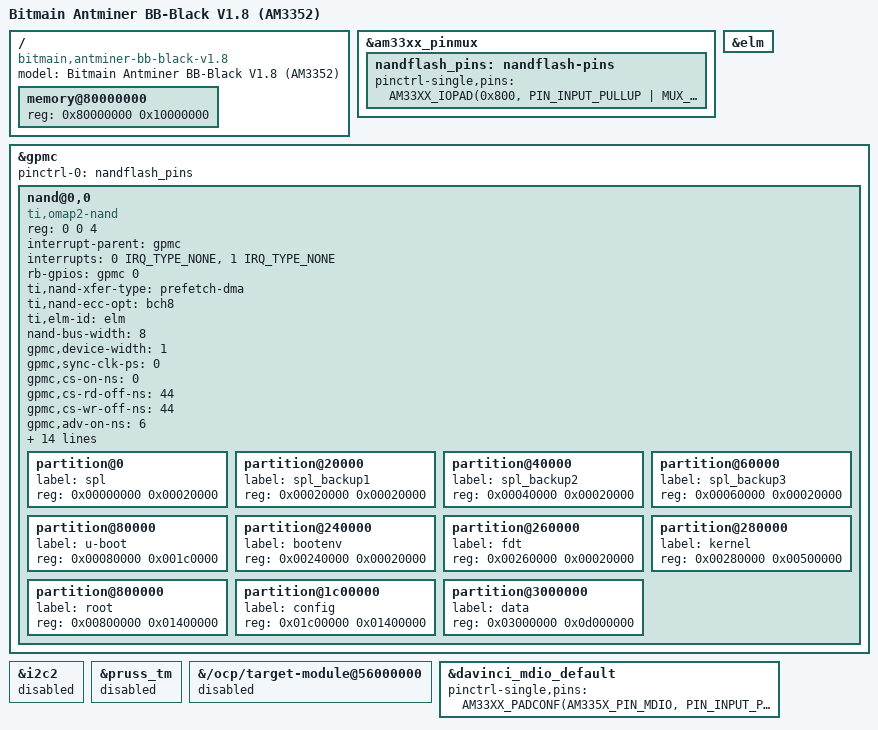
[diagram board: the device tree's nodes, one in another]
// SPDX-License-Identifier: GPL-2.0-only
/*
 * Bitmain Antminer BB-Black V1.8 controller board (AM3352) - fixed part.
 *
 * Everything that is the same on every board: SoC, 256 MiB DDR3, NAND (BCH8+ELM, Bitmain
 * partition layout + 208 MiB "data"), Ethernet (SMSC LAN8710, MII), TPS65217 on I2C0,
 * console UART0, the four BeagleBone user LEDs, microSD slot.
 *
 * Everything per board (pinmux of the free pads, UART1/2/4/5, I2C2, SPI, PWM, CAN, ADC
 * channels, GPIO names/levels) is generated by pinmux/gen-dts.py from a YAML profile into
 * the board .dts that includes this file. Do not add pinmux here.
 *
 * Linux-3.8 label -> mainline label for the UARTs on this SoC:
 *   serial@44e09000 hwmod uart1 -> &uart0 (console, ttyS0)
 *   serial@48022000 hwmod uart2 -> &uart1 ... serial@481aa000 hwmod uart6 -> &uart5
 * GPIO banks: 3.8 "gpio1".."gpio4" hwmods are mainline &gpio0..&gpio3.
 *
 * History (NAND timings, MDIO pin conflict, LED discovery): see repo/firmware/README.md.
 */

#include "am33xx.dtsi"
#include "am335x-bone-common.dtsi"
#include <dt-bindings/gpio/gpio.h>
#include <dt-bindings/interrupt-controller/irq.h>
#include <dt-bindings/pinctrl/am33xx.h>

/ {
	model = "Bitmain Antminer BB-Black V1.8 (AM3352)";
	compatible = "bitmain,antminer-bb-black-v1.8", "ti,am335x-bone", "ti,am33xx";

	/* 256 MiB, same as am335x-bone-common.dtsi default; U-Boot fixes it up anyway */
	memory@80000000 {
		device_type = "memory";
		reg = <0x80000000 0x10000000>;
	};

	/*
	 * LEDs: the four BeagleBone user LEDs (gpio1 21..24, usr0 heartbeat) from
	 * am335x-bone-common.dtsi are the ones physically present on the V1.8 board
	 * (verified by blinking, 2026-10-05). No front panel, no beeper.
	 */
};

/* ------------------------------------------------------------------ pinmux */

&am33xx_pinmux {
	/*
	 * No hogs here: am335x-bone-common.dtsi hogs clkout2 on xdma_event_intr1, which on this
	 * board is a free GPIO (gpio0_20). The generated board .dts sets pinctrl-0 for its GPIOs.
	 */
	/delete-property/ pinctrl-names;
	/delete-property/ pinctrl-0;

	/* GPMC NAND, 8-bit, identical to the Bitmain 3.8 nandflash_pins_s0 */
	nandflash_pins: nandflash-pins {
		pinctrl-single,pins = <
			AM33XX_IOPAD(0x800, PIN_INPUT_PULLUP | MUX_MODE0)	/* gpmc_ad0 */
			AM33XX_IOPAD(0x804, PIN_INPUT_PULLUP | MUX_MODE0)	/* gpmc_ad1 */
			AM33XX_IOPAD(0x808, PIN_INPUT_PULLUP | MUX_MODE0)	/* gpmc_ad2 */
			AM33XX_IOPAD(0x80c, PIN_INPUT_PULLUP | MUX_MODE0)	/* gpmc_ad3 */
			AM33XX_IOPAD(0x810, PIN_INPUT_PULLUP | MUX_MODE0)	/* gpmc_ad4 */
			AM33XX_IOPAD(0x814, PIN_INPUT_PULLUP | MUX_MODE0)	/* gpmc_ad5 */
			AM33XX_IOPAD(0x818, PIN_INPUT_PULLUP | MUX_MODE0)	/* gpmc_ad6 */
			AM33XX_IOPAD(0x81c, PIN_INPUT_PULLUP | MUX_MODE0)	/* gpmc_ad7 */
			AM33XX_IOPAD(0x870, PIN_INPUT_PULLUP | MUX_MODE0)	/* gpmc_wait0 (R/B#) */
			AM33XX_IOPAD(0x874, PIN_INPUT_PULLUP | MUX_MODE7)	/* gpmc_wpn as gpio0_31 */
			AM33XX_IOPAD(0x87c, PIN_OUTPUT | MUX_MODE0)		/* gpmc_csn0 */
			AM33XX_IOPAD(0x890, PIN_OUTPUT | MUX_MODE0)		/* gpmc_advn_ale */
			AM33XX_IOPAD(0x894, PIN_OUTPUT | MUX_MODE0)		/* gpmc_oen_ren */
			AM33XX_IOPAD(0x898, PIN_OUTPUT | MUX_MODE0)		/* gpmc_wen */
			AM33XX_IOPAD(0x89c, PIN_OUTPUT | MUX_MODE0)		/* gpmc_be0n_cle */
		>;
	};
};

/* ------------------------------------------------------------------- NAND */

&elm {
	status = "okay";
};

&gpmc {
	status = "okay";
	pinctrl-names = "default";
	pinctrl-0 = <&nandflash_pins>;
	ranges = <0 0 0x08000000 0x01000000>;	/* CS0: 16 MiB window for NAND */

	nand@0,0 {
		compatible = "ti,omap2-nand";
		reg = <0 0 4>;		/* CS0, offset 0, IO size 4 */
		interrupt-parent = <&gpmc>;
		interrupts = <0 IRQ_TYPE_NONE>,	/* fifoevent */
			     <1 IRQ_TYPE_NONE>;	/* termcount */
		rb-gpios = <&gpmc 0 GPIO_ACTIVE_HIGH>;	/* gpmc_wait0 */

		ti,nand-xfer-type = "prefetch-dma";
		ti,nand-ecc-opt = "bch8";
		ti,elm-id = <&elm>;
		nand-bus-width = <8>;
		gpmc,device-width = <1>;

		/* Timings 1:1 from mainline am335x-evm.dts (same Micron MT29F2G08ABAEAWP). */
		gpmc,sync-clk-ps = <0>;
		gpmc,cs-on-ns = <0>;
		gpmc,cs-rd-off-ns = <44>;
		gpmc,cs-wr-off-ns = <44>;
		gpmc,adv-on-ns = <6>;
		gpmc,adv-rd-off-ns = <34>;
		gpmc,adv-wr-off-ns = <44>;
		gpmc,we-on-ns = <0>;
		gpmc,we-off-ns = <40>;
		gpmc,oe-on-ns = <0>;
		gpmc,oe-off-ns = <54>;
		gpmc,access-ns = <64>;
		gpmc,rd-cycle-ns = <82>;
		gpmc,wr-cycle-ns = <82>;
		gpmc,bus-turnaround-ns = <0>;
		gpmc,cycle2cycle-delay-ns = <0>;
		gpmc,clk-activation-ns = <0>;
		gpmc,wr-access-ns = <40>;
		gpmc,wr-data-mux-bus-ns = <0>;

		/* Must match U-Boot mtdparts and the Bitmain layout exactly */
		#address-cells = <1>;
		#size-cells = <1>;

		partition@0 {
			label = "spl";
			reg = <0x00000000 0x00020000>;
		};
		partition@20000 {
			label = "spl_backup1";
			reg = <0x00020000 0x00020000>;
		};
		partition@40000 {
			label = "spl_backup2";
			reg = <0x00040000 0x00020000>;
		};
		partition@60000 {
			label = "spl_backup3";
			reg = <0x00060000 0x00020000>;
		};
		partition@80000 {
			label = "u-boot";
			reg = <0x00080000 0x001c0000>;
		};
		partition@240000 {
			label = "bootenv";
			reg = <0x00240000 0x00020000>;
		};
		partition@260000 {
			label = "fdt";
			reg = <0x00260000 0x00020000>;
		};
		partition@280000 {
			label = "kernel";
			reg = <0x00280000 0x00500000>;
		};
		partition@800000 {
			label = "root";
			reg = <0x00800000 0x01400000>;
		};
		partition@1c00000 {
			label = "config";
			reg = <0x01c00000 0x01400000>;
		};
		/* the Bitmain layout stops at 48 MiB; the rest of the 256 MiB chip: UBIFS data */
		partition@3000000 {
			label = "data";
			reg = <0x03000000 0x0d000000>;
		};
	};
};

/* -------------------------------------------------------------- I2C / PMIC */

/*
 * i2c0 + TPS65217 come from am335x-bone-common.dtsi. U-Boot talks to the PMIC
 * at 0x24 ("i2c mw 0x24 1 0x3e" in bootcmd), so it is present. There is no
 * baseboard EEPROM at 0x50 on this board.
 */
/delete-node/ &baseboard_eeprom;

/* am335x-bone-common.dtsi enables i2c2 (P9.19/20); it is a per-board choice here */
&i2c2 {
	status = "disabled";
};

/* no cape ID EEPROMs (0x54..0x57) on this board: drop the bone-common nodes so i2c2 shows
 * only what the profile adds */
/delete-node/ &cape_eeprom0;
/delete-node/ &cape_eeprom1;
/delete-node/ &cape_eeprom2;
/delete-node/ &cape_eeprom3;

/* ------------------------------------------------------------ not on AM3352 */

/* AM3352 has no PRU-ICSS; am335x-bone-common.dtsi enables it for AM3358 */
&pruss_tm {
	status = "disabled";
};

/* AM3352 has no SGX either: otherwise "omap_reset_deassert: timedout waiting for gfx" */
&{/ocp/target-module@56000000} {
	status = "disabled";
};

/* ---------------------------------------------------------------- Ethernet */

/*
 * am335x-bone-common.dtsi adds uart0_ctsn (as GPIO, BBB rev C PHY reset) to
 * the MDIO pin group. On this board that pad is uart4_rxd, so keep only the
 * real MDIO pins here.
 */
&davinci_mdio_default {
	pinctrl-single,pins = <
		AM33XX_PADCONF(AM335X_PIN_MDIO, PIN_INPUT_PULLUP | SLEWCTRL_FAST, MUX_MODE0)
		AM33XX_PADCONF(AM335X_PIN_MDC, PIN_OUTPUT_PULLUP, MUX_MODE0)
	>;
};
